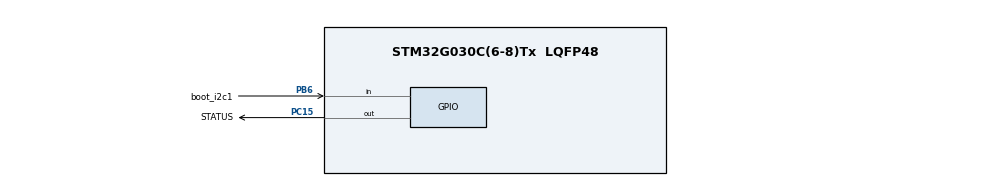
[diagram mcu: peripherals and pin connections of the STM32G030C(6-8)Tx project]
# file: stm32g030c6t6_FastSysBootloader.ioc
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IWDG.Prescaler=IWDG_PRESCALER_256
Mcu.Family=STM32G0
Mcu.Name=STM32G030C(6-8)Tx
Mcu.Package=LQFP48
PA13.Mode=Serial_Wire
PA13.Signal=SYS_SWDIO
PA14-BOOT0.Mode=Serial_Wire
PA14-BOOT0.Signal=SYS_SWCLK
PB6.GPIO_Label=boot_i2c1
PB6.Signal=GPIO_Input
PC15-OSC32_OUT\ (PC15).GPIO_Label=STATUS
PC15-OSC32_OUT\ (PC15).Signal=GPIO_Output
PF0-OSC_IN\ (PF0).Mode=HSE-External-Oscillator
PF0-OSC_IN\ (PF0).Signal=RCC_OSC_IN
PF1-OSC_OUT\ (PF1).Mode=HSE-External-Oscillator
PF1-OSC_OUT\ (PF1).Signal=RCC_OSC_OUT
ProjectManager.HeapSize=0x200
ProjectManager.StackSize=0x400
ProjectManager.TargetToolchain=STM32CubeIDE
RCC.ADCFreq_Value=64000000
RCC.AHBFreq_Value=64000000
RCC.CortexFreq_Value=64000000
RCC.EXTERNAL_CLOCK_VALUE=12288000
RCC.HCLKFreq_Value=64000000
RCC.HSE_VALUE=8000000
RCC.HSI_VALUE=16000000
RCC.LSE_VALUE=32768
RCC.PLLN=16
RCC.PLLSourceVirtual=RCC_PLLSOURCE_HSE
RCC.SYSCLKFreq_VALUE=64000000
RCC.SYSCLKSource=RCC_SYSCLKSOURCE_PLLCLK
RCC.VCOOutputFreq_Value=128000000
VP_IWDG_VS_IWDG.Mode=IWDG_Activate
board=custom

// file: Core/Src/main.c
/* USER CODE BEGIN Header */
/**
 ******************************************************************************
 * @file           : main.c
 * @brief          : Main program body
 ******************************************************************************
 * @attention
 *
 * Copyright (c) 2023 STMicroelectronics.
 * All rights reserved.
 *
 * This software is licensed under terms that can be found in the LICENSE file
 * in the root directory of this software component.
 * If no LICENSE file comes with this software, it is provided AS-IS.
 *
 ******************************************************************************
 */
/* USER CODE END Header */
#include "main.h"

/* USER CODE BEGIN Includes */
#include "ap.h"
/* USER CODE END Includes */

IWDG_HandleTypeDef hiwdg;

void SystemClock_Config(void);
static void MX_GPIO_Init(void);
static void MX_IWDG_Init(void);

int main(void)
{

  /* MCU Configuration--------------------------------------------------------*/

  /* Reset of all peripherals, Initializes the Flash interface and the Systick. */
  HAL_Init();

  /* Configure the system clock */
  SystemClock_Config();

  /* Initialize all configured peripherals */
  MX_GPIO_Init();
  MX_IWDG_Init();
  /* USER CODE BEGIN 2 */
  apInit();
  /* Read GPIO state */

#if 0
  uint32_t gpio_state = LL_GPIO_ReadInputPort(boot_i2c1_GPIO_Port);

  /* Check GPIO state */
  if (gpio_state & boot_i2c1_Pin)
  {
    /* GPIO pin is high */
    //jumpToAddr(0x8000800); // Jump To Firmware
    led_ms = 500;
  }
  else
  {
    /* GPIO pin is low */
    //wdgBegin(2000);
    //jumpToAddr(0x1FFF0000); // Jump To System Bootloader
    led_ms = 1000;
  }

#endif
  apMain();
  /* USER CODE END 2 */

  /* Infinite loop */
  while (1)
  {

    /* USER CODE BEGIN 3 */
    //LL_GPIO_TogglePin(status_GPIO_Port, status_Pin);

//    for (volatile int i = 0; i  < (led_ms*1000); ++i )
//    {
//
//    }

  }
  /* USER CODE END 3 */
}

void SystemClock_Config(void)
{
  LL_FLASH_SetLatency(LL_FLASH_LATENCY_2);
  while(LL_FLASH_GetLatency() != LL_FLASH_LATENCY_2)
  {
  }

  /* HSE configuration and activation */
  LL_RCC_HSE_Enable();
  while(LL_RCC_HSE_IsReady() != 1)
  {
  }

  /* LSI configuration and activation */
  LL_RCC_LSI_Enable();
  while(LL_RCC_LSI_IsReady() != 1)
  {
  }

  /* Main PLL configuration and activation */
  LL_RCC_PLL_ConfigDomain_SYS(LL_RCC_PLLSOURCE_HSE, LL_RCC_PLLM_DIV_1, 16, LL_RCC_PLLR_DIV_2);
  LL_RCC_PLL_Enable();
  LL_RCC_PLL_EnableDomain_SYS();
  while(LL_RCC_PLL_IsReady() != 1)
  {
  }

  /* Set AHB prescaler*/
  LL_RCC_SetAHBPrescaler(LL_RCC_SYSCLK_DIV_1);

  /* Sysclk activation on the main PLL */
  LL_RCC_SetSysClkSource(LL_RCC_SYS_CLKSOURCE_PLL);
  while(LL_RCC_GetSysClkSource() != LL_RCC_SYS_CLKSOURCE_STATUS_PLL)
  {
  }

  /* Set APB1 prescaler*/
  LL_RCC_SetAPB1Prescaler(LL_RCC_APB1_DIV_1);
  /* Update CMSIS variable (which can be updated also through SystemCoreClockUpdate function) */
  LL_SetSystemCoreClock(64000000);

   /* Update the time base */
  if (HAL_InitTick (TICK_INT_PRIORITY) != HAL_OK)
  {
    Error_Handler();
  }
}

static void MX_IWDG_Init(void)
{

  hiwdg.Instance = IWDG;
  hiwdg.Init.Prescaler = IWDG_PRESCALER_256;
  hiwdg.Init.Window = 4095;
  hiwdg.Init.Reload = 4095;
  //if (HAL_IWDG_Init(&hiwdg) != HAL_OK)
  //{
  //  Error_Handler();
  //}

}

static void MX_GPIO_Init(void)
{
  GPIO_InitTypeDef GPIO_InitStruct = {0};

  /* GPIO Ports Clock Enable */
  __HAL_RCC_GPIOC_CLK_ENABLE();
  __HAL_RCC_GPIOF_CLK_ENABLE();
  __HAL_RCC_GPIOA_CLK_ENABLE();
  __HAL_RCC_GPIOB_CLK_ENABLE();

  /*Configure GPIO pin Output Level */
  HAL_GPIO_WritePin(STATUS_GPIO_Port, STATUS_Pin, GPIO_PIN_RESET);

  /*Configure GPIO pin : STATUS_Pin */
  GPIO_InitStruct.Pin = STATUS_Pin;
  GPIO_InitStruct.Mode = GPIO_MODE_OUTPUT_PP;
  GPIO_InitStruct.Pull = GPIO_NOPULL;
  GPIO_InitStruct.Speed = GPIO_SPEED_FREQ_LOW;
  HAL_GPIO_Init(STATUS_GPIO_Port, &GPIO_InitStruct);

  /*Configure GPIO pin : boot_i2c1_Pin */
  GPIO_InitStruct.Pin = boot_i2c1_Pin;
  GPIO_InitStruct.Mode = GPIO_MODE_INPUT;
  GPIO_InitStruct.Pull = GPIO_NOPULL;
  HAL_GPIO_Init(boot_i2c1_GPIO_Port, &GPIO_InitStruct);

}

void Error_Handler(void)
{
  __disable_irq();
  while (1)
  {
  }
}
